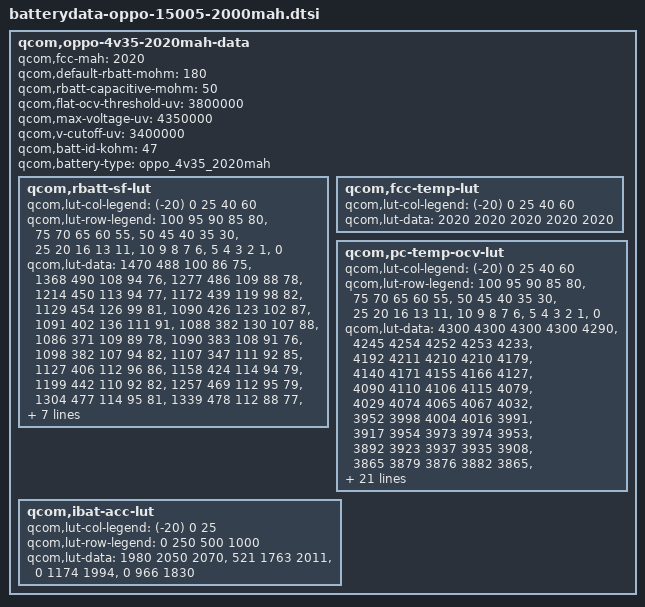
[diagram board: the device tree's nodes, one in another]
/* Copyright (c) 2013, The Linux Foundation. All rights reserved.
 *
 * This program is free software; you can redistribute it and/or modify
 * it under the terms of the GNU General Public License version 2 and
 * only version 2 as published by the Free Software Foundation.
 *
 * This program is distributed in the hope that it will be useful,
 * but WITHOUT ANY WARRANTY; without even the implied warranty of
 * MERCHANTABILITY or FITNESS FOR A PARTICULAR PURPOSE.  See the
 * GNU General Public License for more details.
 */

qcom,oppo-4v35-2020mah-data {
	qcom,fcc-mah = <2020>;
	qcom,default-rbatt-mohm = <180>;
	qcom,rbatt-capacitive-mohm = <50>;
	qcom,flat-ocv-threshold-uv = <3800000>;
	qcom,max-voltage-uv = <4350000>;
	qcom,v-cutoff-uv = <3400000>;
	//qcom,chg-term-ua = <100000>;
	qcom,batt-id-kohm = <47>;
	qcom,battery-type = "oppo_4v35_2020mah";

	qcom,rbatt-sf-lut {
		qcom,lut-col-legend = <(-20) 0 25 40 60>;
		qcom,lut-row-legend = <100 95 90 85 80>,
				<75 70 65 60 55>,
				<50 45 40 35 30>,
				<25 20 16 13 11>,
				<10 9 8 7 6>,
				<5 4 3 2 1>,
				<0>;
		qcom,lut-data = <1470 488 100 86 75>,
				<1368 490 108 94 76>,
				<1277 486 109 88 78>,
				<1214 450 113 94 77>,
				<1172 439 119 98 82>,
				<1129 454 126 99 81>,
				<1090 426 123 102 87>,
				<1091 402 136 111 91>,
				<1088 382 130 107 88>,
				<1086 371 109 89 78>,
				<1090 383 108 91 76>,
				<1098 382 107 94 82>,
				<1107 347 111 92 85>,
				<1127 406 112 96 86>,
				<1158 424 114 94 79>,
				<1199 442 110 92 82>,
				<1257 469 112 95 79>,
				<1304 477 114 95 81>,
				<1339 478 112 88 77>,
				<1363 484 109 92 82>,
				<1374 487 111 98 86>,
				<1386 495 115 99 86>,
				<1398 515 118 101 90>,
				<1409 523 123 104 85>,
				<1421 542 124 104 82>,
				<1433 566 123 101 88>,
				<1444 574 119 99 92>,
				<1456 585 125 102 101>,
				<1468 600 131 105 125>,
				<2924 644 145 120 496>,
				<11696 4386 4386 4386 4386>;

		};

	qcom,fcc-temp-lut {
		qcom,lut-col-legend = <(-20) 0 25 40 60>;
		qcom,lut-data = <2020 2020 2020 2020 2020>;
	};
				
	qcom,pc-temp-ocv-lut {
		qcom,lut-col-legend = <(-20) 0 25 40 60>;
		qcom,lut-row-legend = <100 95 90 85 80>,
				<75 70 65 60 55>,
				<50 45 40 35 30>,
				<25 20 16 13 11>,
				<10 9 8 7 6>,
				<5 4 3 2 1>,
				<0>;
		qcom,lut-data = <4300 4300 4300	4300 4290>,
				<4245 4254 4252	4253 4233>,
				<4192 4211 4210	4210 4179>,
				<4140 4171 4155	4166 4127>,
				<4090 4110 4106	4115 4079>,
				<4029 4074 4065	4067 4032>,
				<3952 3998 4004	4016 3991>,
				<3917 3954 3973	3974 3953>,
				<3892 3923 3937	3935 3908>,
				<3865 3879 3876	3882 3865>,
				<3845 3847 3847	3854 3837>,
				<3821 3824 3824	3832 3816>,
				<3799 3803 3807	3812 3799>,
				<3782 3788 3792	3797 3783>,
				<3768 3777 3779	3780 3755>,
				<3752 3767 3759	3760 3732>,
				<3734 3753 3740	3742 3709>,
				<3714 3729 3717	3716 3683>,
				<3682 3707 3695	3692 3669>,
				<3642 3699 3690	3690 3668>,
				<3620 3697 3689	3690 3667>,
				<3601 3696 3688	3690 3666>,
				<3580 3695 3687	3689 3663>,
				<3560 3691 3686	3687 3647>,
				<3530 3690 3680	3681 3612>,
				<3500 3685 3664	3659 3566>,
				<3460 3667 3622	3619 3506>,
				<3410 3626 3570	3564 3426>,
				<3350 3571 3500	3491 3306>,
				<3150 3497 3400	3390 3108>,
				<3000 3000 3000	3000 3000>;
	};

	qcom,ibat-acc-lut {
		qcom,lut-col-legend = <(-20) 0 25>;
		qcom,lut-row-legend = <0 250 500 1000>;
		qcom,lut-data = <1980 2050 2070>,
				<521 1763 2011>,
				<0 1174 1994>,
				<0 966 1830>;
	};

};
